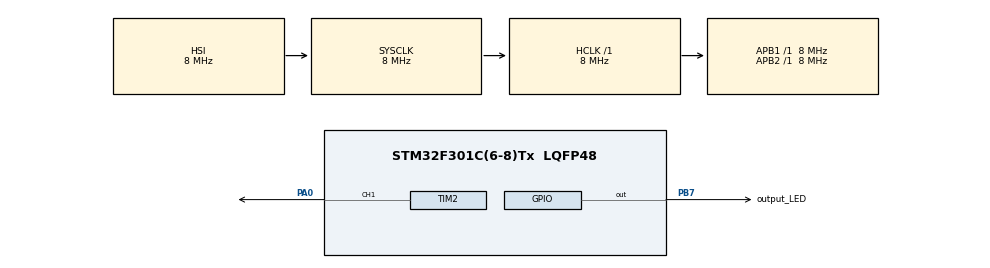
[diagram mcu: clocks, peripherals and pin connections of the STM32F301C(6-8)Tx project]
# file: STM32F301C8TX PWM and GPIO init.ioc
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Mcu.Family=STM32F3
Mcu.Name=STM32F301C(6-8)Tx
Mcu.Package=LQFP48
NVIC.PriorityGroup=NVIC_PRIORITYGROUP_4
PA0.Signal=S_TIM2_CH1_ETR
PA2.Signal=S_TIM2_CH3
PB7.GPIO_Label=output_LED
PB7.GPIO_ModeDefaultOutputPP=GPIO_MODE_OUTPUT_PP
PB7.GPIO_PuPd=GPIO_PULLDOWN
PB7.Signal=GPIO_Output
ProjectManager.HeapSize=0x200
ProjectManager.StackSize=0x400
ProjectManager.TargetToolchain=STM32CubeIDE
RCC.AHBFreq_Value=8000000
RCC.APB1Freq_Value=8000000
RCC.APB2Freq_Value=8000000
RCC.CortexFreq_Value=8000000
RCC.HSE_VALUE=8000000
RCC.HSI_VALUE=8000000
RCC.LSE_VALUE=32768
RCC.SYSCLKFreq_VALUE=8000000
SH.S_TIM2_CH1_ETR.0=TIM2_CH1,PWM Generation1 CH1
SH.S_TIM2_CH3.0=TIM2_CH3
TIM2.AutoReloadPreload=TIM_AUTORELOAD_PRELOAD_ENABLE
TIM2.Channel-PWM\ Generation1\ CH1=TIM_CHANNEL_1
TIM2.Period=255
TIM2.Prescaler=250
TIM2.Pulse-PWM\ Generation1\ CH1=127
VP_TIM2_VS_ClockSourceINT.Mode=Internal
board=custom

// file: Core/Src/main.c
/* USER CODE BEGIN Header */
/**
  ******************************************************************************
  * @file           : main.c
  * @brief          : Main program body
  ******************************************************************************
  * @attention
  *
  * Copyright (c) 2024 STMicroelectronics.
  * All rights reserved.
  *
  * This software is licensed under terms that can be found in the LICENSE file
  * in the root directory of this software component.
  * If no LICENSE file comes with this software, it is provided AS-IS.
  *
  ******************************************************************************
  */
/* USER CODE END Header */
#include "main.h"

TIM_HandleTypeDef htim2;

void SystemClock_Config(void);
static void MX_GPIO_Init(void);
static void MX_TIM2_Init(void);

int main(void)
{

  /* MCU Configuration--------------------------------------------------------*/

  /* Reset of all peripherals, Initializes the Flash interface and the Systick. */
  HAL_Init();

  /* Configure the system clock */
  SystemClock_Config();

  /* Initialize all configured peripherals */
  MX_GPIO_Init();
  MX_TIM2_Init();

  /* Infinite loop */
  while (1)
  {

    /* USER CODE BEGIN 3 */
	  HAL_GPIO_WritePin(output_LED_GPIO_Port, output_LED_Pin,GPIO_PIN_SET);
	  HAL_Delay(500);
	  HAL_GPIO_WritePin(output_LED_GPIO_Port, output_LED_Pin,GPIO_PIN_RESET);
	  HAL_Delay(500);
	  HAL_TIM_PWM_Start(&htim2, TIM_CHANNEL_2);
  }
  /* USER CODE END 3 */
}

void SystemClock_Config(void)
{
  RCC_OscInitTypeDef RCC_OscInitStruct = {0};
  RCC_ClkInitTypeDef RCC_ClkInitStruct = {0};

  /** Initializes the RCC Oscillators according to the specified parameters
  * in the RCC_OscInitTypeDef structure.
  */
  RCC_OscInitStruct.OscillatorType = RCC_OSCILLATORTYPE_HSI;
  RCC_OscInitStruct.HSIState = RCC_HSI_ON;
  RCC_OscInitStruct.HSICalibrationValue = RCC_HSICALIBRATION_DEFAULT;
  RCC_OscInitStruct.PLL.PLLState = RCC_PLL_NONE;
  if (HAL_RCC_OscConfig(&RCC_OscInitStruct) != HAL_OK)
  {
    Error_Handler();
  }

  /** Initializes the CPU, AHB and APB buses clocks
  */
  RCC_ClkInitStruct.ClockType = RCC_CLOCKTYPE_HCLK|RCC_CLOCKTYPE_SYSCLK
                              |RCC_CLOCKTYPE_PCLK1|RCC_CLOCKTYPE_PCLK2;
  RCC_ClkInitStruct.SYSCLKSource = RCC_SYSCLKSOURCE_HSI;
  RCC_ClkInitStruct.AHBCLKDivider = RCC_SYSCLK_DIV1;
  RCC_ClkInitStruct.APB1CLKDivider = RCC_HCLK_DIV1;
  RCC_ClkInitStruct.APB2CLKDivider = RCC_HCLK_DIV1;

  if (HAL_RCC_ClockConfig(&RCC_ClkInitStruct, FLASH_LATENCY_0) != HAL_OK)
  {
    Error_Handler();
  }
}

static void MX_TIM2_Init(void)
{

  TIM_ClockConfigTypeDef sClockSourceConfig = {0};
  TIM_MasterConfigTypeDef sMasterConfig = {0};
  TIM_OC_InitTypeDef sConfigOC = {0};

  htim2.Instance = TIM2;
  htim2.Init.Prescaler = 250;
  htim2.Init.CounterMode = TIM_COUNTERMODE_UP;
  htim2.Init.Period = 255;
  htim2.Init.ClockDivision = TIM_CLOCKDIVISION_DIV1;
  htim2.Init.AutoReloadPreload = TIM_AUTORELOAD_PRELOAD_ENABLE;
  if (HAL_TIM_Base_Init(&htim2) != HAL_OK)
  {
    Error_Handler();
  }
  sClockSourceConfig.ClockSource = TIM_CLOCKSOURCE_INTERNAL;
  if (HAL_TIM_ConfigClockSource(&htim2, &sClockSourceConfig) != HAL_OK)
  {
    Error_Handler();
  }
  if (HAL_TIM_PWM_Init(&htim2) != HAL_OK)
  {
    Error_Handler();
  }
  sMasterConfig.MasterOutputTrigger = TIM_TRGO_RESET;
  sMasterConfig.MasterSlaveMode = TIM_MASTERSLAVEMODE_DISABLE;
  if (HAL_TIMEx_MasterConfigSynchronization(&htim2, &sMasterConfig) != HAL_OK)
  {
    Error_Handler();
  }
  sConfigOC.OCMode = TIM_OCMODE_PWM1;
  sConfigOC.Pulse = 127;
  sConfigOC.OCPolarity = TIM_OCPOLARITY_HIGH;
  sConfigOC.OCFastMode = TIM_OCFAST_DISABLE;
  if (HAL_TIM_PWM_ConfigChannel(&htim2, &sConfigOC, TIM_CHANNEL_1) != HAL_OK)
  {
    Error_Handler();
  }
  HAL_TIM_MspPostInit(&htim2);

}

static void MX_GPIO_Init(void)
{
  GPIO_InitTypeDef GPIO_InitStruct = {0};

  /* GPIO Ports Clock Enable */
  __HAL_RCC_GPIOA_CLK_ENABLE();
  __HAL_RCC_GPIOB_CLK_ENABLE();

  /*Configure GPIO pin Output Level */
  HAL_GPIO_WritePin(output_LED_GPIO_Port, output_LED_Pin, GPIO_PIN_RESET);

  /*Configure GPIO pin : output_LED_Pin */
  GPIO_InitStruct.Pin = output_LED_Pin;
  GPIO_InitStruct.Mode = GPIO_MODE_OUTPUT_PP;
  GPIO_InitStruct.Pull = GPIO_PULLDOWN;
  GPIO_InitStruct.Speed = GPIO_SPEED_FREQ_LOW;
  HAL_GPIO_Init(output_LED_GPIO_Port, &GPIO_InitStruct);

}

void Error_Handler(void)
{
  __disable_irq();
  while (1)
  {
  }
}
